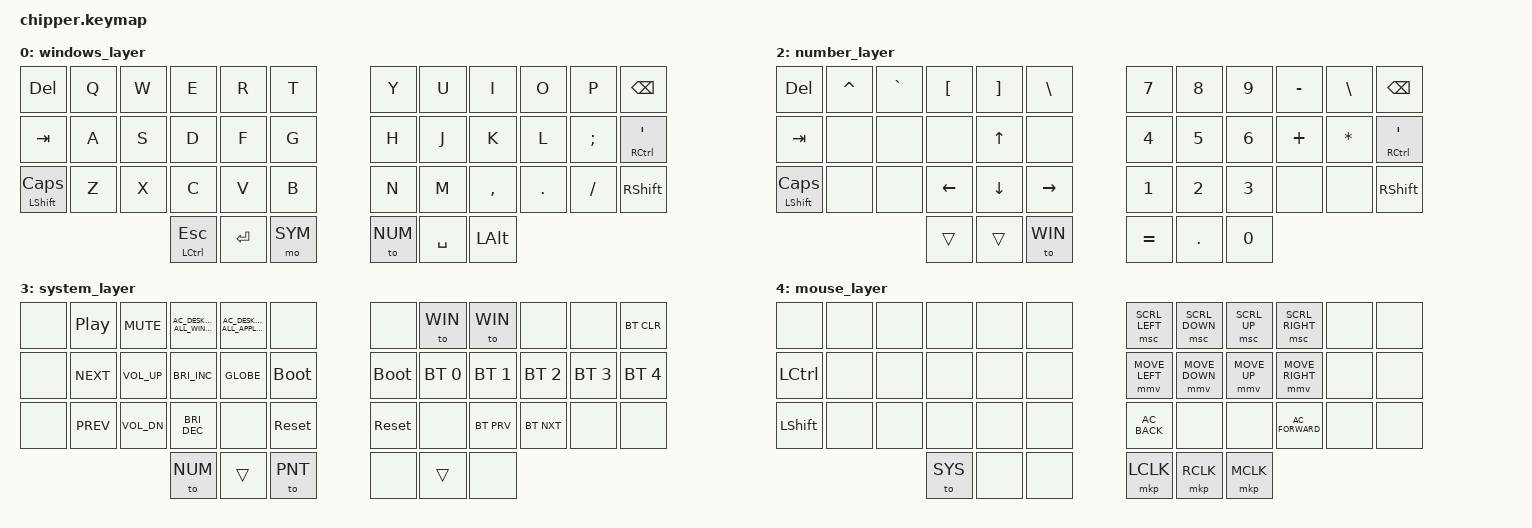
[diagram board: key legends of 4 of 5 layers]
#define ZMK_POINTING_DEFAULT_MOVE_VAL 1700 // default: 600
#define ZMK_POINTING_DEFAULT_SCRL_VAL 30  // default: 10

#include <behaviors.dtsi>
#include <dt-bindings/zmk/keys.h>
#include <dt-bindings/zmk/bt.h>        // bluetooth
#include <dt-bindings/zmk/pointing.h>  // mouse

#define WIN 0  // windows os
#define SYM 1  // symbols
#define NUM 2  // number
#define SYS 3  // system such as media, bluetooth, bootloader, etc
#define PNT 4  // mouse

/ {
    combos {
        compatible = "zmk,combos";

        // One-handed SYS access. Combo-invoked behaviors always run on the
        // central half (combo.c hardcodes source = LOCAL), so reset/bootloader
        // must NOT be bound to combos directly. Instead the combo opens the
        // SYS layer (sticky, ~1s); the following real key press keeps its own
        // source, so &bootloader / &sys_reset run on the half it is pressed on:
        //   left : tap Q+C  then G = bootloader, B = sys_reset
        //   right: tap P+,  then H = bootloader, N = sys_reset
        // Right-half access still requires the halves to be paired; if pairing
        // is broken, use the physical RST button (double-tap) instead.

        combo_sys_left {  // Q + C
            timeout-ms = <50>;
            key-positions = <1 27>;
            bindings = <&sl SYS>;
            layers = <WIN>;
            require-prior-idle-ms = <125>;
        };

        combo_sys_right {  // P + ,
            timeout-ms = <50>;
            key-positions = <10 32>;
            bindings = <&sl SYS>;
            layers = <WIN>;
            require-prior-idle-ms = <125>;
        };
    };

    behaviors {
        my_hold_tap: my_hold_tap {
            compatible = "zmk,behavior-hold-tap";
            #binding-cells = <2>;
            flavor = "tap-preferred";
            tapping-term-ms = <700>;
            bindings = <&kp>, <&kp>;
        };

        ht_snip: hold_tap_snip {
            compatible = "zmk,behavior-hold-tap";
            #binding-cells = <2>;
            flavor = "tap-preferred";
            tapping-term-ms = <200>;
            bindings = <&kp>, <&kp>;
        };

        ht_kp: hold_tap_keypress {
            compatible = "zmk,behavior-hold-tap";
            #binding-cells = <2>;
            tapping-term-ms = <200>;
            quick-tap-ms = <0>;
            flavor = "tap-preferred";
            bindings = <&kp>, <&kp>;
        };
    };

    keymap {
        compatible = "zmk,keymap";

         windows_layer {  // WIN 0
            bindings = <
&kp DEL	&kp Q	&kp W	&kp E	&kp R	&kp T	&kp Y	&kp U	&kp I	&kp O	&kp P	&kp BSPC
&kp TAB	&kp A &kp S &kp D &kp F   	&kp G    	&kp H   	&kp J	&kp K      	&kp L 	&kp SEMI  	&mt RCTRL SQT
&mt LSHIFT CAPS	&kp Z  	&kp X	&kp C &kp V	&kp B	&kp N	&kp M	 &kp COMMA 	  &kp DOT	  &kp FSLH 	 &kp RSHFT
			&mt LCTRL ESC  	&kp RET	 &mo SYM	&to NUM	 &kp SPACE	  &kp LALT			
            >;
        };

        symbols_layer {  // SYM 1
            bindings = <
&kp TILDE	&kp EXCL 	&kp AT	  &kp HASH   	&kp DOLLAR	 &kp PRCNT 	&kp AMPS	  &kp STAR	  &kp LPAR	 &kp RPAR	 &kp UNDER 	&kp PLUS
&kp N1	&kp N2 	 &kp N3	   &kp N4	 &kp N5	 &kp N6	  &kp N7	  &kp N8	  &kp N9	 &kp N0	 &kp UP	  &kp EQUAL
	&none	&none	&none	&none	&none	&none	&none	&trans 	 &kp LEFT	 &kp DOWN	 &kp RIGHT
			&trans 	&trans 	&trans 	&trans 	&trans 	&trans 			
            >;
        };

        number_layer {  // NUM 2
            bindings = <
&kp DEL	&kp CARET	&kp GRAVE	&kp LBKT	&kp RBKT	&kp BACKSLASH	&kp N7	&kp N8	&kp N9	&kp MINUS	&kp BACKSLASH	&kp BSPC
&kp TAB	&none	&none	&none	&kp UP	&none	   &kp N4	 &kp N5	 &kp N6	&kp PLUS	  &kp STAR	&mt RCTRL SQT
&mt LSHIFT CAPS	&none	&none	&kp LEFT	&kp DOWN	&kp RIGHT	&kp N1	&kp N2 	 &kp N3	&none	&none	 &kp RSHFT
			&trans 	&trans 	 &to WIN	 &kp EQUAL	     &kp DOT	  &kp N0			
            >;
        };

        system_layer {  // SYS 3
            bindings = <
&none  &kp C_PP    &kp C_MUTE    &kp C_AC_DESKTOP_SHOW_ALL_WINDOWS  &kp C_AC_DESKTOP_SHOW_ALL_APPLICATIONS  &none         &none        &to WIN       &to WIN       &none         &none         &bt BT_CLR
&none  &kp C_NEXT  &kp C_VOL_UP  &kp C_BRI_INC                      &kp GLOBE                               &bootloader   &bootloader  &bt BT_SEL 0  &bt BT_SEL 1  &bt BT_SEL 2  &bt BT_SEL 3  &bt BT_SEL 4
&none  &kp C_PREV  &kp C_VOL_DN  &kp C_BRI_DEC                      &none                                   &sys_reset    &sys_reset   &none         &bt BT_PRV    &bt BT_NXT    &none         &none
                                 &to NUM                              &trans                                  &to PNT         &none        &trans        &none
            >;
        };

        mouse_layer {  // PNT 4
            bindings = <
&none      &none  &none  &none      &none  &none    &msc SCRL_LEFT  &msc SCRL_DOWN  &msc SCRL_UP  &msc SCRL_RIGHT    &none  &none
&kp LCTRL      &none  &none  &none      &none  &none    &mmv MOVE_LEFT  &mmv MOVE_DOWN  &mmv MOVE_UP  &mmv MOVE_RIGHT    &none  &none
&kp LSHFT  &none  &none  &none      &none  &none    &kp  C_AC_BACK  &none           &none         &kp  C_AC_FORWARD  &none  &none
                         &to SYS  &none  &none    &mkp LCLK       &mkp RCLK       &mkp MCLK
            >;
        };
    };
};
